# CEC1736_S0_2HW device description
Architecture: CORTEX-M4; Family: CEC173X; Series: CEC
Registers are 32-bit, read-write, reset 0x0 unless marked. A register's access mark holds for its fields unless they carry their own. Offsets are from the block's base; [hi:lo] are bit positions; 'fields as' and 'values as' point back to an identical list.

## EC_REG_BANK — This block is designed to be accessed internally by the EC via the register interface.
Instances: EC_REG_BANK 0x4000FC00
0x00 SRAM_CNFG 8-bit — SRAM Configuration Register
  [1:0] SRAM_SIZE — SRAM Configuration Register: 0: 384KB (352k Code, 32k Data) 1: 320kB (288k Code, 32k Data) 2: 256kB (224k Code, 32k Data) 3: Illegal 256kB (224k Code, 32k Data)
0x04 AHB_ERR_ADDR — AHB Error Address [0:0]
0x14 AHB_ERR_CTRL 8-bit — AHB Error Control [0:0] AHB_ERROR_DISABLE, 0: EC memory exceptions are enabled. 1: EC memory exceptions are disabled.
0x18 INTR_CTRL reset 0x1 — Interrupt Control [0:0] NVIC_EN (NVIC_EN) This bit enables Alternate NVIC IRQ's Vectors. The Alternate NVIC Vectors provides each interrupt event with a dedicated (direct) NVIC vector. 0 = Alternate NVIC vectors disabled, 1= Alternate NVIC vectors enabled
0x1C ETM_CTRL — ETM TRACE Enable [0:0] TRACE_EN (TRACE_EN) This bit enables the ARM TRACE debug port (ETM/ITM). The Trace Debug Interface pins are forced to the TRACE functions. 0 = ARM TRACE port disabled, 1= ARM TRACE port enabled
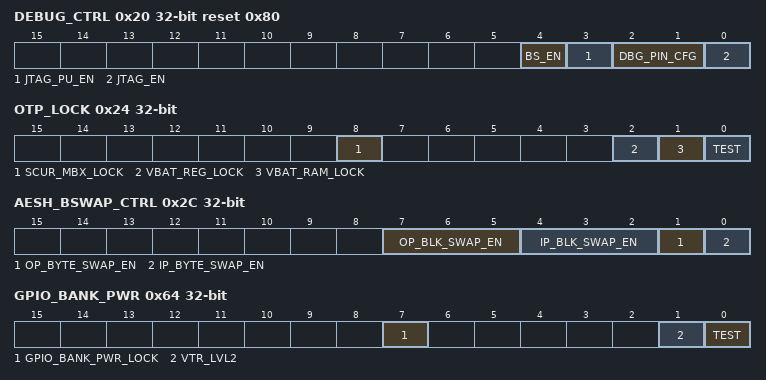
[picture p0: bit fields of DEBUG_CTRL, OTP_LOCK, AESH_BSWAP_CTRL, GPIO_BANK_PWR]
0x20 DEBUG_CTRL reset 0x80 — Debug Enable Register
  [4] BS_EN — This bit sets the boundary scan tap controller accessibility from JTAG port. 1= Boundary scan tap controller accessibile through JTAG Port. 0= Boundary scan tap controller not accessibile through JTAG Port.
  [3] JTAG_PU_EN — If this bit is set to '1b' internal pull-up resistors are automatically enabled on the appropriate debugging port wires whenever the debug port is enabled (the DEBUG_EN bit in this register is '1b' and the JTAG_RST# pin is high). The setting of DEBUG_PIN_CFG determines which pins have pull-ups enabled when the debug port is enabled.
  [2:1] DBG_PIN_CFG — This field determines which pins are affected by the TRST# debug enable pin. 3=Reserved 2=The pins associated with the JTAG TCK and TMS switch to the debug interface when TRST# is de-asserted high. The pins associated with TDI and TDO remain controlled by the associated GPIO. This setting should be used when the ARM Serial Wire Debug (SWD) is required for debugging and the Serial Wire Viewer is not required 1=The pins associated with the JTAG TCK, TMS and TDO switch to the debug interface when TRST# is de-asserted high. The pin associated with TDI remains controlled by the associated GPIO. This setting should be used when the ARM Serial Wire Debug (SWD) and Serial Wire Viewer (SWV) are both required for debugging 0=All four pins associated with JTAG (TCK, TMS, TDI and TDO) switch to the debug interface when TRST# is de-asserted high. This setting should be used when the JTAG TAP controller is required for debugging.
    2=JTAG_TCK_TMS (2=The pins associated with the JTAG TCK and TMS switch to the debug interface when TRST# is de-asserted high. The pins associated with TDI and TDO remain controlled by the associated GPIO. This setting should be used when the ARM Serial Wire Debug (SWD) is required for debugging and the Serial Wire Viewer is not required); 1=JTAG_TCK_TMS_TDO (1=The pins associated with the JTAG TCK, TMS and TDO switch to the debug interface when TRST# is de-asserted high. The pin associated with TDI remains controlled by the associated GPIO. This setting should be used when the ARM Serial Wire Debug (SWD) and Serial Wire Viewer (SWV) are both required for debugging); 0=JTAG_TCK_TMS_TDO_TDI (0=All four pins associated with JTAG (TCK, TMS, TDI and TDO) switch to the debug interface when TRST# is de-asserted high. This setting should be used when the JTAG TAP controller is required for debugging.)
  [0] JTAG_EN — DEBUG_EN (JTAG_EN) This bit enables the JTAG/SWD debug port. 0= JTAG/SWD port disabled. JTAG/SWD cannot be enabled (i.e., the TRST# pin is ignored and the JTAG signals remain in their non-JTAG state) 1= JTAG/SWD port enabled. A high on TRST# enables JTAG or SWD, as determined by SWD_EN.
0x24 OTP_LOCK — Lock Register
  [8] SCUR_MBX_LOCK — Secure Mailbox LOCK. 0 = Not Locked. 1 = Write Locked.
  [2] VBAT_REG_LOCK — VBAT REG LOCK. 0 = Not Locked. 1 = Locked.
  [1] VBAT_RAM_LOCK — VBAT RAM LOCK bit. 0 = Not Locked. 1 = Locked.
  [0] TEST
0x28 WDT_CNT — WDT Event Count [3:0] WDT_COUNT (WDT_COUNT) These EC R/W bits are cleared to 0 on VCC1 POR, but not on a WDT. Note: This field is written by Boot ROM firmware to indicate the number of times a WDT fired before loading a good EC code image.
0x2C AESH_BSWAP_CTRL — AES HASH Byte Swap Control Register.
  [7:5] OP_BLK_SWAP_EN — Used to enable word swap on a DWORD during AHB write from AES / HASH block 0=Disable.
    4=SWAP_128_BYTE_BLOCK (4=Swap 32-bit doublewords in 128-byte blocks); 3=SWAP_64_BYTE_BLOCK (3=Swap doublewords in 64-byte blocks. Useful for SHA-256. Bus references issued in the order 0x3C, 0x38, 0x34, 0x30, 0x2C, 0x28, 0x24, 0x20, 0x1C, 0x18, 0x14, 0x10, 0xC, 0x8, 0x4, 0x0,...); 2=SWAP_16_BYTE_BLOCK (2=Swap doublewords in 16-byte blocks. Useful for AES. Bus references issued in the order 0xC, 0x8, 0x4, 0x0, 0x1C, 0x18,...); 1=SWAP_8_BYTE_BLOCK (1=Swap doublewords in 8-byte blocks. Useful for SHA-512, which works on 64-bit words. Bus references issued in the order 0x4, 0x0, 0xC, 0x8, ...); 0=DIS (0=Disable.)
  [4:2] IP_BLK_SWAP_EN — Used to enable word swap on a DWORD during AHB read from AES / HASH block 0=Disable.
    values as OP_BLK_SWAP_EN
  [1] OP_BYTE_SWAP_EN — Used to enable byte swap on a DWORD during AHB write from AES / HASH block: 1=Enable; 0=Disable.
  [0] IP_BYTE_SWAP_EN — Used to enable byte swap on a DWORD during AHB read from AES / HASH block: 1=Enable; 0=Disable.
0x64 GPIO_BANK_PWR — GPIO Bank Power Register
  [7] GPIO_BANK_PWR_LOCK — GPIO Bank Power Lock. 0: VTR_LEVEL bits[2:0] and GPIO Bank Power Lock bit are R/W 1 = VTR_LEVEL bits[2:0] and GPIO Bank Power Lock bit are Read Only.
  [1] VTR_LVL2 — Voltage value on VTR2. This bit is set by Firmware after a VTR Power On Reset. It must be set by software if the VTR power rail is not active when RESET_SYS is de-asserted. Write access is determined by bit 7. 1=VTR2 is powered by 1.8V 0=VTR2 is powered by 3.3V.
  [0] TEST — This bit must be programmed to 0h for proper operation of the device.
0x70 SRAM_BNK_SWP — Security Monitor SRAM Bank Swap Register
  [0] BNK_SWP — SRAM bank Swap Register
0x90 VW_SRC_CNGF reset 0x7 — Virtual Wire Source Configuration Register
  [2:0] VW_SRC — VWIRE_SOURCE [2], VWIRE_SOURCE [1], VWIRE_SOURCE [0]
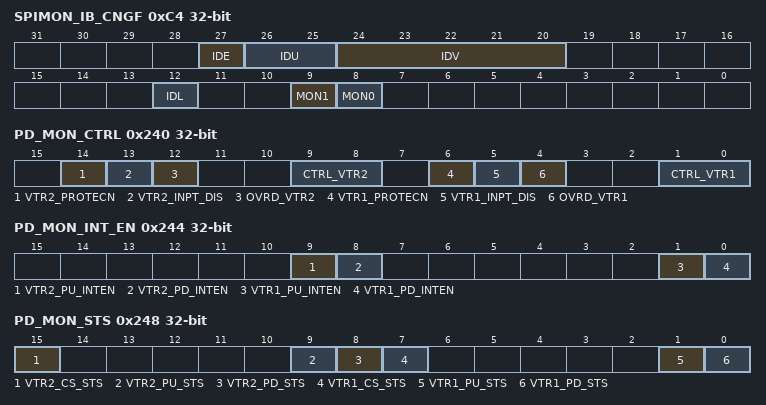
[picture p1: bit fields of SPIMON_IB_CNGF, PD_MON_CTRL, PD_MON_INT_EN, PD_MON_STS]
0xC4 SPIMON_IB_CNGF — SPI Monitor's Inter-Bus Configuration Register
  [27] IDE — Inter-Bus Intervention Enable
  [26:25] IDU — Delay Units
  [24:20] IDV — Delay Value
  [12] IDL — Lock bit for IDE
  [9] MON1 — QSPI1 Monitor 1. 1 = Route QMSPI1 Traffic to Monitor. 0 = Route Host AP1 Traffic to Monitor
  [8] MON0 — QSPI0 Monitor 0. 1 = Route QMSPI0 Traffic to Monitor. 0 = Route Host AP0 Traffic to Monitor
0x240 PD_MON_CTRL — PAD Monitor Control Register
  [14] VTR2_PROTECN — PAD Monitor Override Protect N VTR2.
  [13] VTR2_INPT_DIS — PAD Monitor Override Input Disable VTR2. 0=Normal Operation 1=input_disable
  [12] OVRD_VTR2 — PAD Monitor Override VTR2 0=Normal Operation 1=Override input_disable and pad_protect_n
  [9:8] CTRL_VTR2 — Pad Monitor Control VTR2. 0=OFF, 1=1ms delay, 2=10ms delay, 3=100ms delay
    0=DISABLED; 1=1MS_DEBOUNCE_CNTR (1ms Debounce Counter Enable); 2=10MS_DEBOUNCE_CNTR (10ms Debounce Counter Enable); 3=100MS_DEBOUNCE_CNTR (100ms Debounce Counter Enable)
  [6] VTR1_PROTECN — PAD Monitor Override Protect N VTR1.
  [5] VTR1_INPT_DIS — PAD Monitor Override Input Disable VTR1. 0=Normal Operation 1=input_disable
  [4] OVRD_VTR1 — PAD Monitor Override VTR1 0=Normal Operation 1=Override input_disable and pad_protect_n
  [1:0] CTRL_VTR1 — Pad Monitor Control VTR1. 0=OFF, 1=1ms delay, 2=10ms delay, 3=100ms delay
    values as CTRL_VTR2
0x244 PD_MON_INT_EN — PAD Monitor Interrupt Enable Register
  [9] VTR2_PU_INTEN — Pad Monitor VTR2 Power Up Interrupt Enable
  [8] VTR2_PD_INTEN — Pad Monitor VTR2 Power Down Interrupt Enable.
  [1] VTR1_PU_INTEN — Pad Monitor VTR1 Power Up Interrupt Enable
  [0] VTR1_PD_INTEN — Pad Monitor VTR1 Power Down Interrupt Enable.
0x248 PD_MON_STS — PAD Monitor Status Register
  [15] VTR2_CS_STS — Pad Monitor Current state VTR2
  [9] VTR2_PU_STS — Pad Monitor VTR2 Power Up Status
  [8] VTR2_PD_STS — Pad Monitor VTR2 Power Down Status
  [7] VTR1_CS_STS — Pad Monitor Current state VTR1
  [1] VTR1_PU_STS — Pad Monitor VTR1 Power Up Status
  [0] VTR1_PD_STS — Pad Monitor VTR1 Power Down Status
Value list EC_REG_BANK_SECMON_CNTR_CTRL1__CNT_EVNT_SEL: 0=CH0_CS_ASRT (Channel0 CS Assertion Events); 1=CH0_OPCD_EVNT (Channel0 Opcode Events); 2=CH0_OPCD_VRTN_EVNT (Channel0 Opcode Variation Events); 3=CH0_DATMSMATH (Channel0 Match Monitor Data Mismatch Violation Events); 4=CH0_RTMONOOBVLT (Channel0 RTMON + OOB Violation Events); 5=CH0_OOBVLT_EVNT (Channel0 OOB Violation Events); 8=CH1_CS_ASRT (Channel1 CS Assertion Events); 9=CH1_OPCD_EVNT (Channel1 Opcode Events); 10=CH1_OPCD_VRTN_EVNT (Channel1 Opcode Variation Events); 11=CH1_DATMSMATH (Channel1 Match Monitor Data Mismatch Violation Events); 12=CH1_RTMONOOBVLT (Channel1 RTMON + OOB Violation Events); 13=CH1_OOBVLT_EVNT (Channel1 OOB Violation Events)
